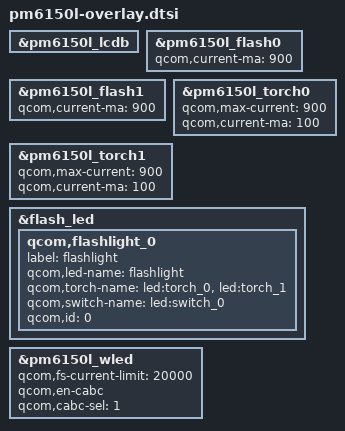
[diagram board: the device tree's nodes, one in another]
/* SPDX-License-Identifier: GPL-2.0 */

&pm6150l_lcdb {
	/delete-property/ qcom,voltage-step-ramp;
};

&pm6150l_flash0 {
	qcom,current-ma = <900>;
};

&pm6150l_flash1 {
	qcom,current-ma = <900>;
};

&pm6150l_torch0 {
	qcom,max-current = <900>;
	qcom,current-ma = <100>;
};

&pm6150l_torch1 {
	qcom,max-current = <900>;
	qcom,current-ma = <100>;
};

&flash_led {
	qcom,flashlight_0{
		label = "flashlight";
		qcom,led-name = "flashlight";
		qcom,torch-name = "led:torch_0","led:torch_1";
		qcom,switch-name = "led:switch_0";
		qcom,id = <0>;
	};
};

&pm6150l_wled {
	qcom,fs-current-limit = <20000>;
	status = "ok";
	qcom,en-cabc;
	qcom,cabc-sel = <1>;
};
